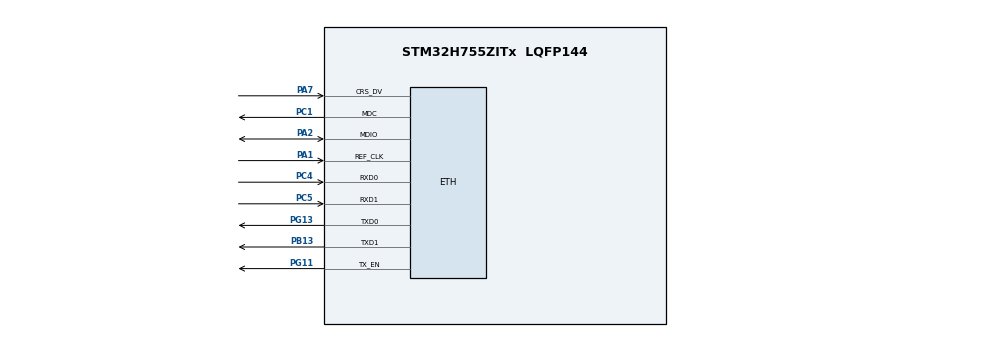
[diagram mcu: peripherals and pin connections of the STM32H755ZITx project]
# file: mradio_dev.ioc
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CORTEX_M7.AccessPermission_S-Cortex_Memory_Protection_Unit_Region1_Settings_S=MPU_REGION_FULL_ACCESS
CORTEX_M7.AccessPermission_S-Cortex_Memory_Protection_Unit_Region2_Settings_S=MPU_REGION_FULL_ACCESS
CORTEX_M7.AccessPermission_S-Cortex_Memory_Protection_Unit_Region3_Settings_S=MPU_REGION_FULL_ACCESS
CORTEX_M7.BaseAddress_S-Cortex_Memory_Protection_Unit_Region1_Settings_S=0x30040000
CORTEX_M7.BaseAddress_S-Cortex_Memory_Protection_Unit_Region2_Settings_S=0x30020000
CORTEX_M7.BaseAddress_S-Cortex_Memory_Protection_Unit_Region3_Settings_S=0x38000000
CORTEX_M7.CPU_DCache=Enabled
CORTEX_M7.CPU_ICache=Enabled
CORTEX_M7.DisableExec_S-Cortex_Memory_Protection_Unit_Region1_Settings_S=MPU_INSTRUCTION_ACCESS_DISABLE
CORTEX_M7.DisableExec_S-Cortex_Memory_Protection_Unit_Region2_Settings_S=MPU_INSTRUCTION_ACCESS_DISABLE
CORTEX_M7.Enable_S-Cortex_Memory_Protection_Unit_Region1_Settings_S=MPU_REGION_ENABLE
CORTEX_M7.Enable_S-Cortex_Memory_Protection_Unit_Region2_Settings_S=MPU_REGION_ENABLE
CORTEX_M7.Enable_S-Cortex_Memory_Protection_Unit_Region3_Settings_S=MPU_REGION_ENABLE
CORTEX_M7.IsBufferable_S-Cortex_Memory_Protection_Unit_Region1_Settings_S=MPU_ACCESS_NOT_BUFFERABLE
CORTEX_M7.IsShareable_S-Cortex_Memory_Protection_Unit_Region1_Settings_S=MPU_ACCESS_SHAREABLE
CORTEX_M7.IsShareable_S-Cortex_Memory_Protection_Unit_Region2_Settings_S=MPU_ACCESS_SHAREABLE
CORTEX_M7.IsShareable_S-Cortex_Memory_Protection_Unit_Region3_Settings_S=MPU_ACCESS_SHAREABLE
CORTEX_M7.Size_S-Cortex_Memory_Protection_Unit_Region1_Settings_S=MPU_REGION_SIZE_32KB
CORTEX_M7.Size_S-Cortex_Memory_Protection_Unit_Region2_Settings_S=MPU_REGION_SIZE_32KB
CORTEX_M7.Size_S-Cortex_Memory_Protection_Unit_Region3_Settings_S=MPU_REGION_SIZE_64KB
CORTEX_M7.SubRegionDisable_S-Cortex_Memory_Protection_Unit_Region1_Settings_S=0
CORTEX_M7.TypeExtField_S-Cortex_Memory_Protection_Unit_Region1_Settings_S=MPU_TEX_LEVEL1
CORTEX_M7.TypeExtField_S-Cortex_Memory_Protection_Unit_Region2_Settings_S=MPU_TEX_LEVEL1
CORTEX_M7.TypeExtField_S-Cortex_Memory_Protection_Unit_Region3_Settings_S=MPU_TEX_LEVEL1
CORTEX_M7.default_mode_Activation=1
CortexM4.IPs=CORTEX_M4\:I,FATFS_M4\:I,FREERTOS_M4\:I,IWDG2\:I,OPENAMP_M4\:I,PDM2PCM_M4\:I,PWR,RCC,RESMGR_UTILITY,SYS_M4\:I,USB_DEVICE_M4\:I,USB_HOST_M4\:I,VREFBUF,WWDG2\:I,GPIO,DMA,BDMA,MDMA,NVIC2\:I
CortexM7.IPs=CORTEX_M7\:I,FATFS_M7\:I,FREERTOS_M7\:I,IWDG1\:I,OPENAMP_M7\:I,PDM2PCM_M7\:I,PWR\:I,RCC\:I,RESMGR_UTILITY\:I,SYS\:I,USB_DEVICE_M7\:I,USB_HOST_M7\:I,VREFBUF\:I,WWDG1\:I,GPIO\:I,DMA\:I,BDMA\:I,MDMA\:I,NVIC1\:I,ETH\:I,TIM6\:I
ETH.ETH_RX_DESC_CNT=12
ETH.MediaInterface=HAL_ETH_RMII_MODE
ETH.RxBufferAddress=0x30040180
ETH.RxDescAddress=0x30040000
ETH.TxDescAddress=0x30040120
FREERTOS_M7.Tasks01=ethTask,24,512,startEthTask,Default,NULL,Dynamic,NULL,NULL
Mcu.Family=STM32H7
Mcu.Name=STM32H755ZITx
Mcu.Package=LQFP144
NVIC1.ETH_IRQn=true\:5\:0\:false\:false\:true\:true\:true\:true\:true
NVIC1.PriorityGroup=NVIC_PRIORITYGROUP_4
NVIC1.TIM6_DAC_IRQn=true\:15\:0\:false\:false\:true\:false\:false\:true\:true
NVIC1.TimeBase=TIM6_DAC_IRQn
NVIC1.TimeBaseIP=TIM6
NVIC2.PriorityGroup=NVIC_PRIORITYGROUP_4
PA1.GPIO_Speed_Default_HIGH=GPIO_SPEED_FREQ_VERY_HIGH
PA1.Mode=RMII
PA1.PinAttribute=CortexM7
PA1.Signal=ETH_REF_CLK
PA2.GPIO_Speed_Default_HIGH=GPIO_SPEED_FREQ_VERY_HIGH
PA2.Mode=RMII
PA2.PinAttribute=CortexM7
PA2.Signal=ETH_MDIO
PA7.GPIO_Speed_Default_HIGH=GPIO_SPEED_FREQ_VERY_HIGH
PA7.Mode=RMII
PA7.PinAttribute=CortexM7
PA7.Signal=ETH_CRS_DV
PB13.GPIO_Speed_Default_HIGH=GPIO_SPEED_FREQ_VERY_HIGH
PB13.Mode=RMII
PB13.PinAttribute=CortexM7
PB13.Signal=ETH_TXD1
PC1.GPIO_Speed_Default_HIGH=GPIO_SPEED_FREQ_VERY_HIGH
PC1.Mode=RMII
PC1.PinAttribute=CortexM7
PC1.Signal=ETH_MDC
PC4.GPIO_Speed_Default_HIGH=GPIO_SPEED_FREQ_VERY_HIGH
PC4.Mode=RMII
PC4.PinAttribute=CortexM7
PC4.Signal=ETH_RXD0
PC5.GPIO_Speed_Default_HIGH=GPIO_SPEED_FREQ_VERY_HIGH
PC5.Mode=RMII
PC5.PinAttribute=CortexM7
PC5.Signal=ETH_RXD1
PG11.GPIO_Speed_Default_HIGH=GPIO_SPEED_FREQ_VERY_HIGH
PG11.Mode=RMII
PG11.PinAttribute=CortexM7
PG11.Signal=ETH_TX_EN
PG13.GPIO_Speed_Default_HIGH=GPIO_SPEED_FREQ_VERY_HIGH
PG13.Mode=RMII
PG13.PinAttribute=CortexM7
PG13.Signal=ETH_TXD0
PH0-OSC_IN\ (PH0).Mode=HSE-External-Clock-Source
PH0-OSC_IN\ (PH0).PinAttribute=Free
PH0-OSC_IN\ (PH0).Signal=RCC_OSC_IN
ProjectManager.HeapSize=M4-0x200,M7-0x200
ProjectManager.StackSize=M4-0x400,M7-0x400
ProjectManager.TargetToolchain=CMake
RCC.ADCFreq_Value=50390625
RCC.APB1Freq_Value=100000000
RCC.APB2Freq_Value=100000000
RCC.APB3Freq_Value=100000000
RCC.APB4Freq_Value=100000000
RCC.CortexFreq_Value=400000000
RCC.D1PPRE=RCC_APB3_DIV2
RCC.D2PPRE1=RCC_APB1_DIV2
RCC.D2PPRE2=RCC_APB2_DIV2
RCC.D3PPRE=RCC_APB4_DIV2
RCC.DIVM1=2
RCC.DIVN1=64
RCC.HCLKFreq_Value=200000000
RCC.HPRE=RCC_HCLK_DIV2
RCC.PLL2FRACN=0
RCC.PLL3FRACN=0
RCC.PLLFRACN=0
RCC.PLLSourceVirtual=RCC_PLLSOURCE_HSE
RCC.SYSCLKFreq_VALUE=400000000
RCC.SYSCLKSource=RCC_SYSCLKSOURCE_PLLCLK
RCC.USBFreq_Value=400000000
SYS.userName=SYS_M7
VP_FREERTOS_M7_VS_CMSIS_V2.Mode=CMSIS_V2
VP_SYS_M4_VS_Systick.Mode=SysTick
VP_SYS_VS_tim6.Mode=TIM6
board=custom

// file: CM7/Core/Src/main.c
/* USER CODE BEGIN Header */
/**
  ******************************************************************************
  * @file           : main.c
  * @brief          : Main program body
  ******************************************************************************
  * @attention
  *
  * Copyright (c) 2026 STMicroelectronics.
  * All rights reserved.
  *
  * This software is licensed under terms that can be found in the LICENSE file
  * in the root directory of this software component.
  * If no LICENSE file comes with this software, it is provided AS-IS.
  *
  ******************************************************************************
  */
/* USER CODE END Header */
#include "main.h"
#include "string.h"
#include "FreeRTOS.h"
#include "cmsis_os2.h"

/* USER CODE BEGIN Includes */
#include <string.h>
/* USER CODE END Includes */

/* USER CODE BEGIN PD */

/* DUAL_CORE_BOOT_SYNC_SEQUENCE: Define for dual core boot synchronization    */
/*                             demonstration code based on hardware semaphore */
/* This define is present in both CM7/CM4 projects                            */
/* To comment when developping/debugging on a single core                     */
#define DUAL_CORE_BOOT_SYNC_SEQUENCE

#if defined(DUAL_CORE_BOOT_SYNC_SEQUENCE)
#ifndef HSEM_ID_0
#define HSEM_ID_0 (0U) /* HW semaphore 0*/
#endif
#endif /* DUAL_CORE_BOOT_SYNC_SEQUENCE */

/* USER CODE END PD */

#if defined ( __ICCARM__ ) /*!< IAR Compiler */
#pragma location=0x30040000
ETH_DMADescTypeDef  DMARxDscrTab[ETH_RX_DESC_CNT]; /* Ethernet Rx DMA Descriptors */
#pragma location=0x30040120
ETH_DMADescTypeDef  DMATxDscrTab[ETH_TX_DESC_CNT]; /* Ethernet Tx DMA Descriptors */

#elif defined ( __CC_ARM )  /* MDK ARM Compiler */

__attribute__((at(0x30040000))) ETH_DMADescTypeDef  DMARxDscrTab[ETH_RX_DESC_CNT]; /* Ethernet Rx DMA Descriptors */
__attribute__((at(0x30040120))) ETH_DMADescTypeDef  DMATxDscrTab[ETH_TX_DESC_CNT]; /* Ethernet Tx DMA Descriptors */

#elif defined ( __GNUC__ ) /* GNU Compiler */

ETH_DMADescTypeDef DMARxDscrTab[ETH_RX_DESC_CNT] __attribute__((section(".RxDescripSection"))); /* Ethernet Rx DMA Descriptors */
ETH_DMADescTypeDef DMATxDscrTab[ETH_TX_DESC_CNT] __attribute__((section(".TxDescripSection")));   /* Ethernet Tx DMA Descriptors */
#endif

ETH_TxPacketConfig TxConfig;

ETH_HandleTypeDef heth;

/* Definitions for ethTask */
osThreadId_t ethTaskHandle;
const osThreadAttr_t ethTask_attributes = {
  .name = "ethTask",
  .stack_size = 512 * 4,
  .priority = (osPriority_t) osPriorityNormal,
};

void SystemClock_Config(void);
static void MPU_Config(void);
static void MX_GPIO_Init(void);
static void MX_ETH_Init(void);
void startEthTask(void *argument);

int main(void)
{

/* USER CODE BEGIN Boot_Mode_Sequence_0 */
#if defined(DUAL_CORE_BOOT_SYNC_SEQUENCE)
  int32_t timeout;
#endif /* DUAL_CORE_BOOT_SYNC_SEQUENCE */
/* USER CODE END Boot_Mode_Sequence_0 */

  /* MPU Configuration--------------------------------------------------------*/
  MPU_Config();

  /* Enable the CPU Cache */

  /* Enable I-Cache---------------------------------------------------------*/
  SCB_EnableICache();

  /* Enable D-Cache---------------------------------------------------------*/
  SCB_EnableDCache();

/* USER CODE BEGIN Boot_Mode_Sequence_1 */
#if defined(DUAL_CORE_BOOT_SYNC_SEQUENCE)
  /* Wait until CPU2 boots and enters in stop mode or timeout*/
  timeout = 0xFFFF;
  while((__HAL_RCC_GET_FLAG(RCC_FLAG_D2CKRDY) != RESET) && (timeout-- > 0));
  if ( timeout < 0 )
  {
  Error_Handler();
  }
#endif /* DUAL_CORE_BOOT_SYNC_SEQUENCE */
/* USER CODE END Boot_Mode_Sequence_1 */
  /* MCU Configuration--------------------------------------------------------*/

  /* Reset of all peripherals, Initializes the Flash interface and the Systick. */
  HAL_Init();

  /* USER CODE BEGIN Init */
  postInit();
  /* USER CODE END Init */

  /* Configure the system clock */
  SystemClock_Config();
/* USER CODE BEGIN Boot_Mode_Sequence_2 */
#if defined(DUAL_CORE_BOOT_SYNC_SEQUENCE)
/* When system initialization is finished, Cortex-M7 will release Cortex-M4 by means of
HSEM notification */
/*HW semaphore Clock enable*/
__HAL_RCC_HSEM_CLK_ENABLE();
/*Take HSEM */
HAL_HSEM_FastTake(HSEM_ID_0);
/*Release HSEM in order to notify the CPU2(CM4)*/
HAL_HSEM_Release(HSEM_ID_0,0);
/* wait until CPU2 wakes up from stop mode */
timeout = 0xFFFF;
while((__HAL_RCC_GET_FLAG(RCC_FLAG_D2CKRDY) == RESET) && (timeout-- > 0));
if ( timeout < 0 )
{
Error_Handler();
}
#endif /* DUAL_CORE_BOOT_SYNC_SEQUENCE */
/* USER CODE END Boot_Mode_Sequence_2 */

  /* Initialize all configured peripherals */
  MX_GPIO_Init();
  MX_ETH_Init();

  /* Init scheduler */
  osKernelInitialize();

  /* Create the thread(s) */
  /* creation of ethTask */
  ethTaskHandle = osThreadNew(startEthTask, NULL, &ethTask_attributes);

  /* Start scheduler */
  osKernelStart();

  /* We should never get here as control is now taken by the scheduler */

  /* Infinite loop */
  while (1)
  {

  }
}

void SystemClock_Config(void)
{
  RCC_OscInitTypeDef RCC_OscInitStruct = {0};
  RCC_ClkInitTypeDef RCC_ClkInitStruct = {0};

  /** Supply configuration update enable
  */
  HAL_PWREx_ConfigSupply(PWR_DIRECT_SMPS_SUPPLY);

  /** Configure the main internal regulator output voltage
  */
  __HAL_PWR_VOLTAGESCALING_CONFIG(PWR_REGULATOR_VOLTAGE_SCALE1);

  while(!__HAL_PWR_GET_FLAG(PWR_FLAG_VOSRDY)) {}

  /** Initializes the RCC Oscillators according to the specified parameters
  * in the RCC_OscInitTypeDef structure.
  */
  RCC_OscInitStruct.OscillatorType = RCC_OSCILLATORTYPE_HSE;
  RCC_OscInitStruct.HSEState = RCC_HSE_BYPASS;
  RCC_OscInitStruct.PLL.PLLState = RCC_PLL_ON;
  RCC_OscInitStruct.PLL.PLLSource = RCC_PLLSOURCE_HSE;
  RCC_OscInitStruct.PLL.PLLM = 2;
  RCC_OscInitStruct.PLL.PLLN = 64;
  RCC_OscInitStruct.PLL.PLLP = 2;
  RCC_OscInitStruct.PLL.PLLQ = 2;
  RCC_OscInitStruct.PLL.PLLR = 2;
  RCC_OscInitStruct.PLL.PLLRGE = RCC_PLL1VCIRANGE_3;
  RCC_OscInitStruct.PLL.PLLVCOSEL = RCC_PLL1VCOWIDE;
  RCC_OscInitStruct.PLL.PLLFRACN = 0;
  if (HAL_RCC_OscConfig(&RCC_OscInitStruct) != HAL_OK)
  {
    Error_Handler();
  }

  /** Initializes the CPU, AHB and APB buses clocks
  */
  RCC_ClkInitStruct.ClockType = RCC_CLOCKTYPE_HCLK|RCC_CLOCKTYPE_SYSCLK
                              |RCC_CLOCKTYPE_PCLK1|RCC_CLOCKTYPE_PCLK2
                              |RCC_CLOCKTYPE_D3PCLK1|RCC_CLOCKTYPE_D1PCLK1;
  RCC_ClkInitStruct.SYSCLKSource = RCC_SYSCLKSOURCE_PLLCLK;
  RCC_ClkInitStruct.SYSCLKDivider = RCC_SYSCLK_DIV1;
  RCC_ClkInitStruct.AHBCLKDivider = RCC_HCLK_DIV2;
  RCC_ClkInitStruct.APB3CLKDivider = RCC_APB3_DIV2;
  RCC_ClkInitStruct.APB1CLKDivider = RCC_APB1_DIV2;
  RCC_ClkInitStruct.APB2CLKDivider = RCC_APB2_DIV2;
  RCC_ClkInitStruct.APB4CLKDivider = RCC_APB4_DIV2;

  if (HAL_RCC_ClockConfig(&RCC_ClkInitStruct, FLASH_LATENCY_2) != HAL_OK)
  {
    Error_Handler();
  }
}

static void MX_ETH_Init(void)
{

   static uint8_t MACAddr[6];

  heth.Instance = ETH;
  MACAddr[0] = 0x00;
  MACAddr[1] = 0x80;
  MACAddr[2] = 0xE1;
  MACAddr[3] = 0x00;
  MACAddr[4] = 0x00;
  MACAddr[5] = 0x00;
  heth.Init.MACAddr = &MACAddr[0];
  heth.Init.MediaInterface = HAL_ETH_RMII_MODE;
  heth.Init.TxDesc = DMATxDscrTab;
  heth.Init.RxDesc = DMARxDscrTab;
  heth.Init.RxBuffLen = 1536;

  if (HAL_ETH_Init(&heth) != HAL_OK)
  {
    Error_Handler();
  }

  memset(&TxConfig, 0 , sizeof(ETH_TxPacketConfig));
  TxConfig.Attributes = ETH_TX_PACKETS_FEATURES_CSUM | ETH_TX_PACKETS_FEATURES_CRCPAD;
  TxConfig.ChecksumCtrl = ETH_CHECKSUM_IPHDR_PAYLOAD_INSERT_PHDR_CALC;
  TxConfig.CRCPadCtrl = ETH_CRC_PAD_INSERT;

}

static void MX_GPIO_Init(void)
{

  /* GPIO Ports Clock Enable */
  __HAL_RCC_GPIOC_CLK_ENABLE();
  __HAL_RCC_GPIOA_CLK_ENABLE();
  __HAL_RCC_GPIOB_CLK_ENABLE();
  __HAL_RCC_GPIOG_CLK_ENABLE();

}

void startEthTask(void *argument)
{
  /* USER CODE BEGIN 5 */
  ethInit();

  /* Infinite loop */
  for(;;)
  {
    checkRxBuf();
    osDelay(1);
  }
  /* USER CODE END 5 */
}

 /* MPU Configuration */

void MPU_Config(void)
{
  MPU_Region_InitTypeDef MPU_InitStruct = {0};

  /* Disables the MPU */
  HAL_MPU_Disable();

  /** Initializes and configures the Region and the memory to be protected
  */
  MPU_InitStruct.Enable = MPU_REGION_ENABLE;
  MPU_InitStruct.Number = MPU_REGION_NUMBER0;
  MPU_InitStruct.BaseAddress = 0x0;
  MPU_InitStruct.Size = MPU_REGION_SIZE_4GB;
  MPU_InitStruct.SubRegionDisable = 0x87;
  MPU_InitStruct.TypeExtField = MPU_TEX_LEVEL0;
  MPU_InitStruct.AccessPermission = MPU_REGION_NO_ACCESS;
  MPU_InitStruct.DisableExec = MPU_INSTRUCTION_ACCESS_DISABLE;
  MPU_InitStruct.IsShareable = MPU_ACCESS_SHAREABLE;
  MPU_InitStruct.IsCacheable = MPU_ACCESS_NOT_CACHEABLE;
  MPU_InitStruct.IsBufferable = MPU_ACCESS_NOT_BUFFERABLE;

  HAL_MPU_ConfigRegion(&MPU_InitStruct);

  /** Initializes and configures the Region and the memory to be protected
  */
  MPU_InitStruct.Number = MPU_REGION_NUMBER1;
  MPU_InitStruct.BaseAddress = 0x30040000;
  MPU_InitStruct.Size = MPU_REGION_SIZE_32KB;
  MPU_InitStruct.SubRegionDisable = 0;
  MPU_InitStruct.TypeExtField = MPU_TEX_LEVEL1;
  MPU_InitStruct.AccessPermission = MPU_REGION_FULL_ACCESS;

  HAL_MPU_ConfigRegion(&MPU_InitStruct);

  /** Initializes and configures the Region and the memory to be protected
  */
  MPU_InitStruct.Number = MPU_REGION_NUMBER2;
  MPU_InitStruct.BaseAddress = 0x30020000;
  MPU_InitStruct.SubRegionDisable = 0x0;

  HAL_MPU_ConfigRegion(&MPU_InitStruct);

  /** Initializes and configures the Region and the memory to be protected
  */
  MPU_InitStruct.Number = MPU_REGION_NUMBER3;
  MPU_InitStruct.BaseAddress = 0x38000000;
  MPU_InitStruct.Size = MPU_REGION_SIZE_64KB;
  MPU_InitStruct.DisableExec = MPU_INSTRUCTION_ACCESS_ENABLE;

  HAL_MPU_ConfigRegion(&MPU_InitStruct);
  /* Enables the MPU */
  HAL_MPU_Enable(MPU_PRIVILEGED_DEFAULT);

}

void HAL_TIM_PeriodElapsedCallback(TIM_HandleTypeDef *htim)
{
  if (htim->Instance == TIM6)
  {
    HAL_IncTick();
  }
}

void Error_Handler(void)
{
  __disable_irq();
  while (1)
  {
  }
}

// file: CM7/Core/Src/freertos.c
/* USER CODE BEGIN Header */
/**
  ******************************************************************************
  * File Name          : freertos.c
  * Description        : Code for freertos applications
  ******************************************************************************
  * @attention
  *
  * Copyright (c) 2026 STMicroelectronics.
  * All rights reserved.
  *
  * This software is licensed under terms that can be found in the LICENSE file
  * in the root directory of this software component.
  * If no LICENSE file comes with this software, it is provided AS-IS.
  *
  ******************************************************************************
  */
/* USER CODE END Header */

#include "FreeRTOS.h"
#include "task.h"
#include "main.h"

/* USER CODE BEGIN Application */
volatile char* failed_task_name = NULL;
void vApplicationStackOverflowHook(TaskHandle_t xTask, char *pcTaskName)
{
  (void)xTask;
  failed_task_name = pcTaskName;
  taskDISABLE_INTERRUPTS();
  while(1) {}
}
/* USER CODE END Application */
